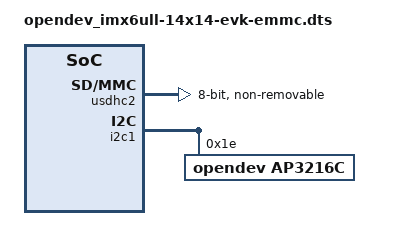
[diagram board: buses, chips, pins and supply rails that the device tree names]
/*
 * Copyright 2019 NXP
 *
 * This program is free software; you can redistribute it and/or
 * modify it under the terms of the GNU General Public License
 * as published by the Free Software Foundation; either version 2
 * of the License, or (at your option) any later version.
 */

#include "imx6ull-14x14-evk.dts"

&usdhc2 {
	pinctrl-names = "default", "state_100mhz", "state_200mhz";
	pinctrl-0 = <&pinctrl_usdhc2_8bit>;
	pinctrl-1 = <&pinctrl_usdhc2_8bit_100mhz>;
	pinctrl-2 = <&pinctrl_usdhc2_8bit_200mhz>;
	bus-width = <8>;
	non-removable;
	status = "okay";
};

/*
// I2C 控制器1 的 pinctrl 节点，已经在 imx6ull-14x14-evk.dtsi 中定义，
// 所以不需要再定义
pinctrl_i2c1: i2c1grp {
	fsl,pins = <
		MX6UL_PAD_UART4_TX_DATA__I2C1_SCL 0x4001b8b0
		MX6UL_PAD_UART4_RX_DATA__I2C1_SDA 0x4001b8b0
	>;
}
*/

// I2C 设备节点（I2C 总线 + I2C 设备）
&i2c1 {
	// 在 imx6ull-14x14-evk.dtsi 中屏蔽了其他的节点
	// line 259
	// I2C 总线节点已经定义，所以只需要添加 I2C 设备节点
	ap3216c@1e {
		compatible = "opendev,ap3216c";
		reg = <0x1e>;
	};
};
